# NM1500_v1 register map
File version: 1.0
Registers are 32-bit, read-write, reset 0x0 unless marked. A register's access mark holds for its fields unless they carry their own. Offsets are from the block's base; [hi:lo] are bit positions; 'fields as' and 'values as' point back to an identical list.

## BPWM — BPWM Register Map
Base 0x40040000
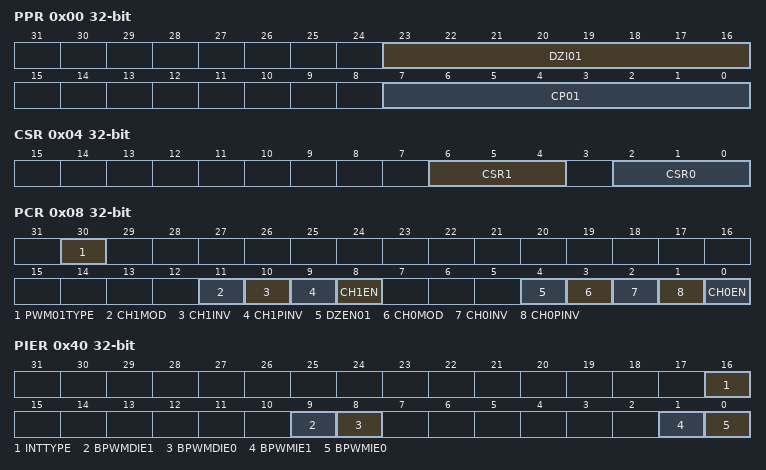
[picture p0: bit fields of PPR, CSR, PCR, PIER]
0x00 PPR — Basic PWM Pre-scalar Register
  [23:16] DZI01 — Dead-zone Interval for Pair of Channel 0 and Channel 1. These 8-bit determine the Dead-zone length.
  [7:0] CP01 — Clock Prescaler. Clock input is divided by (CP01 + 1) before it is fed to the corresponding PWM-timer
0x04 CSR — Basic PWM Clock Source Divider Select Register
  [6:4] CSR1 — PWM Timer 1 Clock Source Divider Selection
  [2:0] CSR0 — PWM Timer 0 Clock Source Divider Selection. Select clock source divider for PWM timer 0. (Table is the same as CSR1)
0x08 PCR — Basic PWM Control Register
  [30] PWM01TYPE — PWM01 Aligned Type Selection Bit
    0=Edge-aligned type; 1=Center-aligned type
  [11] CH1MOD — PWM-Timer 1 Auto-reload/One-Shot Mode. Note: If there is a transition at this bit, it will cause CNR1 and CMR1 be cleared.
    0=One-shot mode; 1=Auto-reload mode
  [10] CH1INV — PWM-Timer 1 Output Inverter Enable
    0=Inverter Disabled; 1=Inverter Enabled
  [9] CH1PINV — PWM-Timer 1 Output Polar Inverse Enable
    0=PWM1 output polar inverse Disabled; 1=PWM1 output polar inverse Enabled
  [8] CH1EN — PWM-Timer 1 Enable
    0=Corresponding PWM-Timer Stopped; 1=Corresponding PWM-Timer Start Running
  [4] DZEN01 — Dead-zone 0 Generator Enable. Note: When Dead-zone generator is enabled, the pair of PWM0 and PWM1 becomes a complementary pair.
    0=Disabled; 1=Enabled
  [3] CH0MOD — PWM-Timer 0 Auto-reload/One-Shot Mode. Note: If there is a transition at this bit, it will cause CNR0 and CMR0 be cleared.
    0=One-shot mode; 1=Auto-reload mode
  [2] CH0INV — PWM-Timer 0 Output Inverter Enable
    0=Inverter Disabled; 1=Inverter Enabled
  [1] CH0PINV — PWM-Timer 0 Output Polar Inverse Enable
    0=PWM0 output polar inverse Disabled; 1=PWM0 output polar inverse Enabled
  [0] CH0EN — PWM-Timer 0 Enable
    0=The corresponding PWM-Timer stops running; 1=The corresponding PWM-Timer starts running
0x0C CNR0 — Basic PWM Counter Register 0
  [15:0] CNRx — PWM Timer Loaded Value. CNR determines the PWM period. Note: Any write to CNR will take effect in next PWM cycle. Note: When PWM operating at Center-aligned type, CNR value should be set between 0x0000 to 0xFFFE. If CNR equal to 0xFFFF, the PWM will work unpredictable. Note: When CNR value is set to 0, PWM output is always high.
0x10 CMR0 — Basic PWM Comparator Register 0
  [15:0] CMRx — PWM Comparator Register. CMR determines the PWM duty. Note: Any write to CNR will take effect in next PWM cycle.
0x14 PDR0 ro — Basic PWM Data Register 0
  [15:0] PDRx — PWM Data Register. User can monitor PDR to know the current value in 16-bit counter.
0x18 CNR1 — Basic PWM Counter Register 0
  fields as CNR0
0x1C CMR1 — Basic PWM Comparator Register 0
  fields as CMR0
0x20 PDR1 ro — Basic PWM Data Register 0
  fields as PDR0
0x40 PIER — Basic PWM Interrupt Enable Register
  [16] INTTYPE — BPWM Interrupt Period Type Selection Bit. Note: This bit is effective when BPWM in Center-aligned type only.
    0=BPWMIFn will be set if BPWM counter underflow; 1=BPWMIFn will be set if BPWM counter matches CNRn register
  [9] BPWMDIE1 — BPWM channel 1 Duty Interrupt Enable
    0=Disabled; 1=Enabled
  [8] BPWMDIE0 — BPWM channel 0 Duty Interrupt Enable
    0=Disabled; 1=Enabled
  [1] BPWMIE1 — BPWM channel 1 Period Interrupt Enable
    0=Disabled; 1=Enabled
  [0] BPWMIE0 — BPWM channel 0 Period Interrupt Enable
    0=Disabled; 1=Enabled
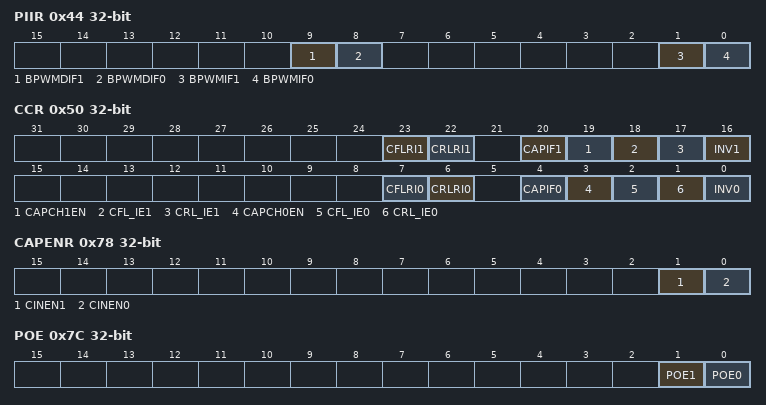
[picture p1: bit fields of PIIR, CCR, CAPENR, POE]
0x44 PIIR — Basic PWM Interrupt Indication Register
  [9] BPWMDIF1 — BPWM Channel 1 Duty Interrupt Flag. Flag is set by hardware when channel 1 BPWM counter down count and reaches CMR1, software can clear this bit by writing a one to it. Note: If CMR equal to CNR, this flag is not working in Edge-aligned type selection
  [8] BPWMDIF0 — BPWM Channel 0 Duty Interrupt Flag. Flag is set by hardware when channel 0 BPWM counter down count and reaches CMR0, software can clear this bit by writing a one to it. Note: If CMR equal to CNR, this flag is not working in Edge-aligned type selection
  [1] BPWMIF1 — BPWM channel 1 Period Interrupt Status. This bit is set by hardware when BPWM1 counter reaches the requirement of interrupt (depend on INTTYPE bit of PIER register), software can write 1 to clear this bit to 0.
  [0] BPWMIF0 — BPWM channel 0 Period Interrupt Status. This bit is set by hardware when BPWM0 counter reaches the requirement of interrupt (depend on INTTYPE bit of PIER register), software can write 1 to clear this bit to 0.
0x50 CCR — Basic PWM Capture Control Register
  [23] CFLRI1 — CFLR1 Latched Indicator Bit. When BPWM input channel 1 has a falling transition, CFLR1 was latched with the value of BPWM down-counter and this bit is set by hardware. Software can write 1 to clear this bit to 0
  [22] CRLRI1 — CRLR1 Latched Indicator Bit. When BPWM input channel 1 has a rising transition, CRLR1 was latched with the value of BPWM down-counter and this bit is set by hardware. Software can write 1 to clear this bit to0.
  [20] CAPIF1 — Channel 1 Capture Interrupt Indication Flag. Write 1 to clear this bit to 0.
  [19] CAPCH1EN — Channel 1 Capture Function Enable. When Enabled, Capture latched the BPWM-counter and saved to CRLR (Rising latch) and CFLR (Falling latch). When Disabled, Capture does not update CRLR and CFLR, and disable PWM channel 1 Interrupt.
    0=Capture function on BPWM channel 1 Disabled; 1=Capture function on BPWM channel 1 Enabled
  [18] CFL_IE1 — Channel 1 Falling Latch Interrupt Enable. When Enabled, if Capture detects BPWM channel 1 has falling transition, Capture will issue an Interrupt.
    0=Falling latch interrupt Disabled; 1=Falling latch interrupt Enabled
  [17] CRL_IE1 — Channel 1 Rising Latch Interrupt Enable. When Enabled, if Capture detects BPWM channel 1 has rising transition, Capture will issue an Interrupt.
    0=Rising latch interrupt Disabled; 1=Rising latch interrupt Enabled
  [16] INV1 — Channel 1 Inverter Enable
    0=Inverter Disabled; 1=Inverter Enabled. Reverse the input signal from GPIO before fed to Capture timer
  [7] CFLRI0 — CFLR0 Latched Indicator Bit. When BPWM input channel 0 has a falling transition, CFLR0 was latched with the value of BPWM down-counter and this bit is set by hardware. Software can write 1 to clear this bit to0.
  [6] CRLRI0 — CRLR0 Latched Indicator Bit. When BPWM input channel 0 has a rising transition, CRLR0 was latched with the value of BPWM down-counter and this bit is set by hardware. Software can write 1 to clear this bit to 0.
  [4] CAPIF0 — Channel 0 Capture Interrupt Indication Flag. Write 1 to clear this bit to 0.
  [3] CAPCH0EN — Channel 0 Capture Function Enable. When Enabled, Capture latched the BPWM-counter value and saved to CRLR (Rising latch) and CFLR (Falling latch). When Disabled, Capture does not update CRLR and CFLR, and disable BPWM channel 0 Interrupt.
    0=Capture function on BPWM channel 0 Disabled; 1=Capture function on BPWM channel 0 Enabled
  [2] CFL_IE0 — Channel 0 Falling Latch Interrupt Enable. When Enabled, if Capture detects BPWM channel 0 has falling transition, Capture will issue an Interrupt.
    values as CFL_IE1
  [1] CRL_IE0 — Channel 0 Rising Latch Interrupt Enable. When Enabled, if Capture detects BPWM channel 0 has rising transition, Capture will issue an Interrupt.
    values as CRL_IE1
  [0] INV0 — Channel 0 Inverter Enable
    values as INV1
0x58 CRLR0 ro — Basic PWM Capture Rising Latch Register (Channel 0)
  [15:0] CRLRx — Capture Rising Latch Register. Latch the BPWM counter when Channel 0/1 has rising transition.
0x5C CFLR0 ro — Basic PWM Capture Falling Latch Register (Channel 0)
  [15:0] CFLRx — Capture Falling Latch Register. Latch the BPWM counter when Channel 0/1 has Falling transition.
0x60 CRLR1 ro — Basic PWM Capture Rising Latch Register (Channel 0)
  fields as CRLR0
0x64 CFLR1 ro — Basic PWM Capture Falling Latch Register (Channel 0)
  fields as CFLR0
0x78 CAPENR — Basic PWM Capture Input Enable Register
  [1] CINEN1 — Channel 1 Capture Input Enable
    0=BPWM Channel 1 capture input path Disabled. The input of BPWM channel 1 capture function is always regarded as 0; 1=BPWM Channel 1 capture input path Enabled. The input of BPWM channel 1 capture function comes from correlative multifunction pin if GPIO multi-function is set as PWM21
  [0] CINEN0 — Channel 0 Capture Input Enable
    0=BPWM Channel 0 capture input path Disabled. The input of BPWM channel 0 capture function is always regarded as 0; 1=BPWM Channel 0 capture input path Enabled. The input of BPWM channel 0 capture function comes from correlative multifunction pin if GPIO multi-function is set as PWM20
0x7C POE — Basic PWM Output Enable
  [1] POE1 — Channel 1 Output Enable Register. Note: The corresponding GPIO pin must also be switched to BPWM function
    0=BPWM channel 1 output to pin Disabled; 1=BPWM channel 1 output to pin Enabled
  [0] POE0 — Channel 0 Output Enable Register. Note: The corresponding GPIO pin must also be switched to BPWM function
    0=BPWM channel 0 output to pin Disabled; 1=BPWM channel 0 output to pin Enabled
